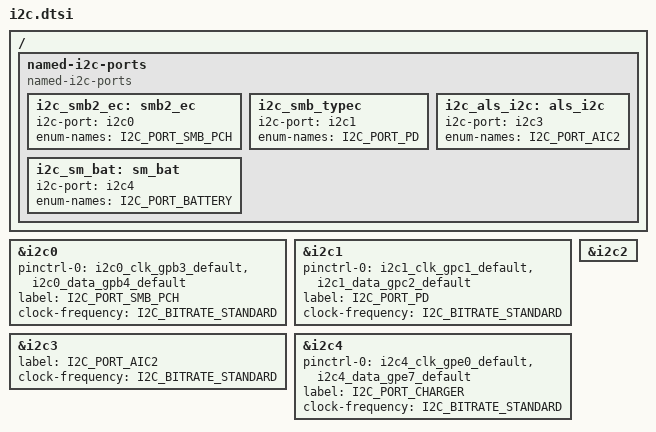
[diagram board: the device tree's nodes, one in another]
/* Copyright 2024 The ChromiumOS Authors
 * Use of this source code is governed by a BSD-style license that can be
 * found in the LICENSE file.
 */

/ {
	named-i2c-ports {
		compatible = "named-i2c-ports";

		i2c_smb2_ec: smb2_ec {
			i2c-port = <&i2c0>;
			enum-names = "I2C_PORT_SMB_PCH";
		};
		i2c_smb_typec: i2c_smb_typec {
			i2c-port = <&i2c1>;
			enum-names = "I2C_PORT_PD";
		};
		i2c_als_i2c: als_i2c {
			i2c-port = <&i2c3>;
			enum-names = "I2C_PORT_AIC2";
		};
		i2c_sm_bat: sm_bat {
			i2c-port = <&i2c4>;
			enum-names = "I2C_PORT_BATTERY";
		};
	};
};

&i2c0 {
	status = "okay";
	pinctrl-0 = <&i2c0_clk_gpb3_default
		&i2c0_data_gpb4_default>;
	pinctrl-names = "default";

	label = "I2C_PORT_SMB_PCH";
	clock-frequency = <I2C_BITRATE_STANDARD>;
};

&i2c1 {
	status = "okay";
	pinctrl-0 = <&i2c1_clk_gpc1_default
		     &i2c1_data_gpc2_default>;
	pinctrl-names = "default";

	label = "I2C_PORT_PD";
	clock-frequency = <I2C_BITRATE_STANDARD>;
};

&i2c2 {
	/delete-property/ scl-gpios;
	/delete-property/ sda-gpios;
};

&i2c3 {
	label = "I2C_PORT_AIC2";
	clock-frequency = <I2C_BITRATE_STANDARD>;
};

/* TODO(b/358612639)
 * Arbitrage generates an incorrect node label when using alternate pins.
 * Create a 2nd node label on I2C3 as a workaround.
 */
i2c3ALT: &i2c3 {
};

&i2c3ALT {
	status = "okay";
	pinctrl-0 = <&i2c3_clk_gph1_default
		&i2c3_data_gph2_default>;
	pinctrl-names = "default";
};

&i2c4 {
	status = "okay";
	pinctrl-0 = <&i2c4_clk_gpe0_default
		     &i2c4_data_gpe7_default>;
	pinctrl-names = "default";

	label = "I2C_BATTERY";
	label = "I2C_PORT_CHARGER";
	clock-frequency = <I2C_BITRATE_STANDARD>;
};
